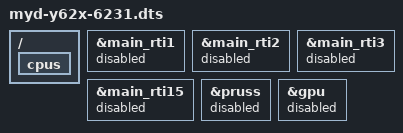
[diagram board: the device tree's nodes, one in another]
// SPDX-License-Identifier: GPL-2.0
/*
 * AM625 SK: https://www.ti.com/lit/zip/sprr448
 *
 * Copyright (C) 2021-2022 Texas Instruments Incorporated - https://www.ti.com/
 */

/dts-v1/;

#include <dt-bindings/leds/common.h>
#include <dt-bindings/gpio/gpio.h>
#include <dt-bindings/net/ti-dp83867.h>
#include "myd-y62x-common.dtsi"

/ {
	cpus {
		/delete-node/ cpu-map;
		/delete-node/ cpu@1;
		/delete-node/ cpu@2;
		/delete-node/ cpu@3;
	};
};
//6231 shut down tree watchdog pruss and gpu
&main_rti1{
	status = "disabled";
};

&main_rti2{
	status = "disabled";
};

&main_rti3{
	status = "disabled";
};

&main_rti15{
	status = "disabled";
};

&pruss {
	status = "disabled";
};

&gpu{
	status = "disabled";
};
